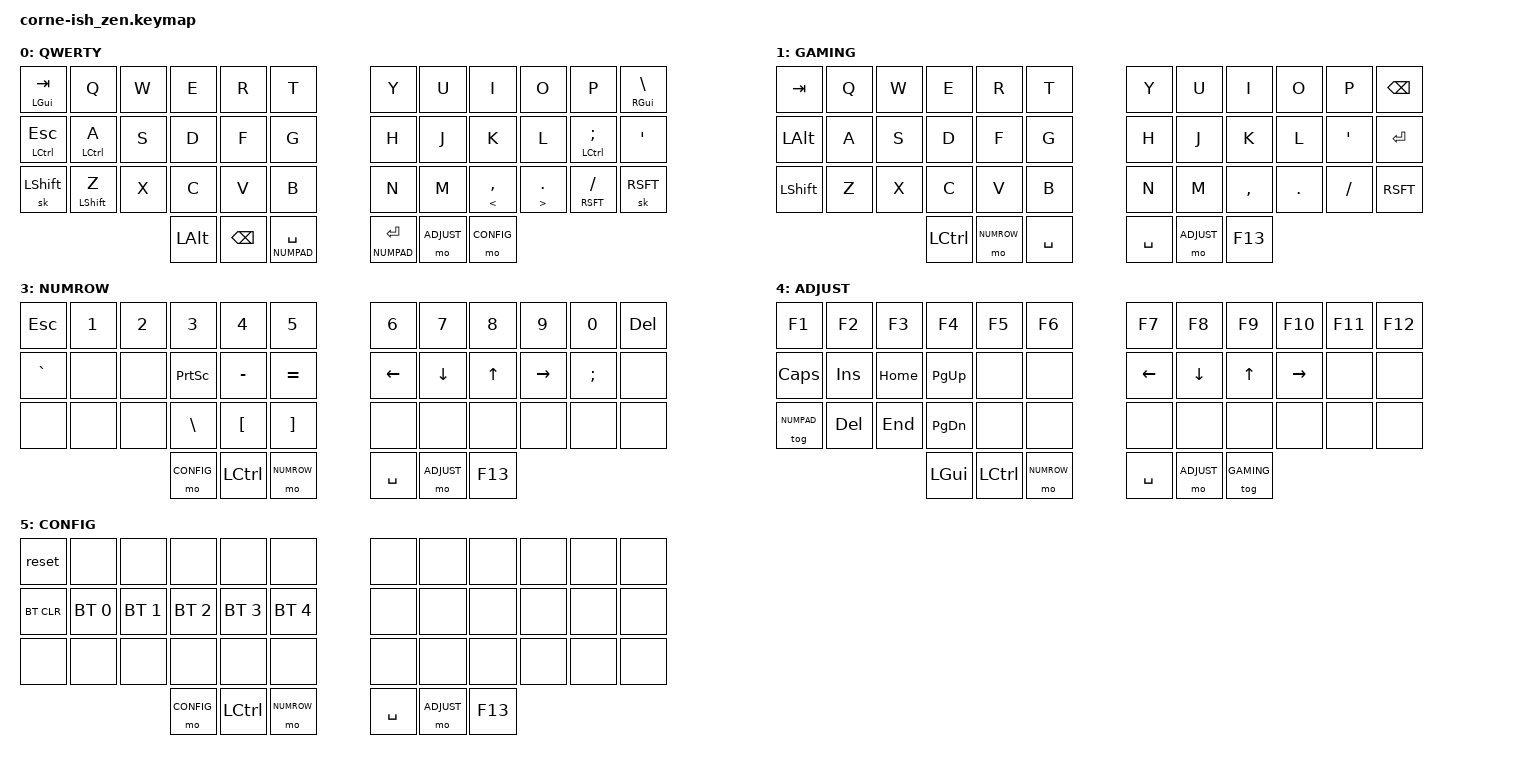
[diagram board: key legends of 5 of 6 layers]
/*
*
* Copyright (c) 2021 lowprokb.ca
* SPDX-License-Identifier: MIT
*
*/

#include <behaviors.dtsi>
#include <dt-bindings/zmk/keys.h>
#include <dt-bindings/zmk/bt.h>

#define QWERTY 0
#define GAMING 1
#define NUMPAD 2
#define NUMROW 3
#define ADJUST 4
#define CONFIG 5

/ {
      behaviors {
        as: autoshift {
                compatible = "zmk,behavior-hold-tap";
                label = "AUTOSHIFT";
                #binding-cells = <2>;
                tapping-term-ms = <200>;
                quick_tap_ms = <0>;
                flavor = "tap-preferred";
                bindings = <&kp>, <&kp>;
            };
       };

       combos {
           compatible = "zmk,combos";
           combo_esc {
               timeout-ms = <50>;
               key-positions = <13 14>;
               bindings = <&kp ESC>;
           };
       };

        keymap {
                compatible = "zmk,keymap";

                default_layer {
                        label = "QWERTY";
                        bindings = <
   &mt LGUI TAB  &kp Q       &kp W &kp E &kp R &kp T         &kp Y &kp U &kp I       &kp O      &kp P          &mt RGUI BSLH
   &mt LCTRL ESC &as LCTRL A &kp S &kp D &kp F &kp G         &kp H &kp J &kp K       &kp L      &as LCTL SEMI  &kp SQT
   &sk LSHFT     &mt LSHFT Z &kp X &kp C &kp V &kp B         &kp N &kp M &as LT CMMA &as GT DOT &mt RSFT FSLH  &sk RSFT
                  &kp LALT &kp BSPC &lt NUMPAD SPACE     &lt NUMPAD RET &mo ADJUST &mo CONFIG
                        >;
                };

                gaming_layer {
                        label = "GAMING";
                        bindings = <
   &kp TAB   &kp Q &kp W &kp E &kp R &kp T    &kp Y &kp U &kp I    &kp O   &kp P    &kp BKSP
   &kp LALT  &kp A &kp S &kp D &kp F &kp G    &kp H &kp J &kp K    &kp L   &kp QUOT &kp ENTER
   &kp LSHFT &kp Z &kp X &kp C &kp V &kp B    &kp N &kp M &kp CMMA &kp DOT &kp FSLH &kp RSFT
               &kp LCTL &mo NUMROW &kp SPC    &kp SPC &mo ADJUST &kp F13
                        >;
                };

                numpad_layer {
                        label = "NUMPAD";
                        bindings = <
   &kp TAB   &none   &none   &kp LBRC &kp RBRC  &kp PIPE    &kp KP_EQUAL    &as AMPS N7    &as STAR N8    &kp N9       &as UNDER MINUS &kp BSPC
   &kp &none &kp SQT &kp DQT &kp LPAR &kp RPAR  &kp GRAVE   &kp KP_ASTERISK &as DOLLAR N4  &as PERCENT N5 &as CARET N6 &as EQUAL PLUS  &none
   &sk LSHFT &none   &none   &kp LBKT &kp RBKT  &kp TILDE   &kp KP_SLASH    &as EXCL N1    &as AT N2      &as HASH N3  &kp ENTER       &none
              &mo CONFIG &kp LCTL &mo NUMROW    &kp SPC &kp N0 &kp DOT
                        >;
                };

                numrow_layer {
                        label = "NUMROW";
                        bindings = <
   &kp ESC   &kp N1 &kp N2 &kp N3    &kp N4    &kp N5       &kp N6   &kp N7   &kp N8 &kp N9    &kp N0   &kp DEL
   &kp GRAVE &none  &none  &kp PSCRN &kp MINUS &kp EQUAL    &kp LEFT &kp DOWN &kp UP &kp RIGHT &kp SEMI &none
   &none     &none  &none  &kp BSLH  &kp LBKT  &kp RBKT     &none    &none    &none  &none     &none    &none
                          &mo CONFIG &kp LCTL &mo NUMROW    &kp SPC &mo ADJUST &kp F13
                        >;
                };

                adjust_layer {
                        label = "ADJUST";
                        bindings = <
   &kp F1      &kp F2  &kp F3   &kp F4    &kp F5 &kp F6    &kp F7   &kp F8   &kp F9 &kp F10   &kp F11 &kp F12
   &kp CAPS    &kp INS &kp HOME &kp PG_UP &none  &none     &kp LEFT &kp DOWN &kp UP &kp RIGHT &none   &none
   &tog NUMPAD &kp DEL &kp END  &kp PG_DN &none  &none     &none    &none    &none  &none     &none   &none
                           &kp LGUI &kp LCTL &mo NUMROW    &kp SPC &mo ADJUST &tog GAMING
                        >;
                };

                config_layer {
                        label = "CONFIG";
                        bindings = <
   &reset     &none        &none        &none        &none        &none           &none &none &none &none &none &none 
   &bt BT_CLR &bt BT_SEL 0 &bt BT_SEL 1 &bt BT_SEL 2 &bt BT_SEL 3 &bt BT_SEL 4    &none &none &none &none &none &none
   &none      &none        &none        &none        &none        &none           &none &none &none &none &none &none
                                                &mo CONFIG &kp LCTL &mo NUMROW    &kp SPC &mo ADJUST &kp F13
                        >;
                };
        };
};
